# DA14531 register map
Vendor: Dialog; Series: DA14531; File version: 1.2
CPU: CM0 r1p0, little endian, MPU, FPU, 3 interrupt priority bits
Registers are 16-bit, read-write, reset 0x0 unless marked. A register's access mark holds for its fields unless they carry their own. Offsets are from the block's base; [hi:lo] are bit positions.

## SPI — SPI registers
Base 0x50001200
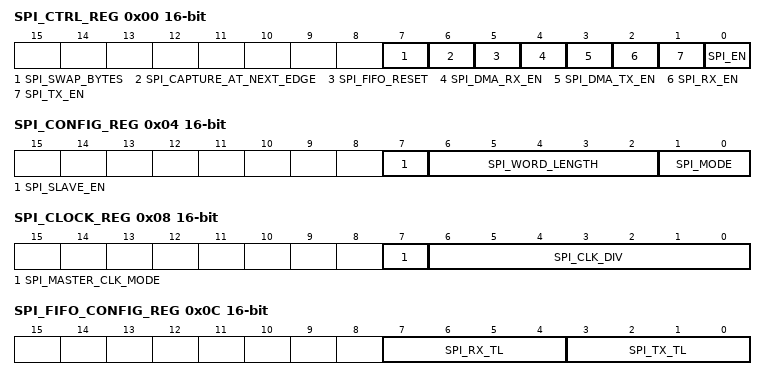
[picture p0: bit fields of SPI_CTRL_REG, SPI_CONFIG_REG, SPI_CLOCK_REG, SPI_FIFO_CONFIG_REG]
0x00 SPI_CTRL_REG — Spi control register
  [7] SPI_SWAP_BYTES — 0 = normal operation 1 = LSB and MSB are swaped in APB interface In case of 8bit spi interface, DMA/SPI can be configured in 16bit mode to off load the bus. Enabling SPI_SWAP_BYTES bytes will read/wrte correctly
  [6] SPI_CAPTURE_AT_NEXT_EDGE — 0 = SPI captures data at correct clock edge 1 = SPI captures data at next clock edge. (only for Master mode and high clock)
  [5] SPI_FIFO_RESET — 0 = Fifo normal operation 1 = Fifo in reset state
  [4] SPI_DMA_RX_EN — applicable only when SPI_RX_EN=1 0 = No DMA request for RX 1 = DMA request when SPI_STATUS_RX_FULL='1'
  [3] SPI_DMA_TX_EN — applicable only when SPI_TX_EN=1 0 = No DMA request for TX 1 = DMA request when SPI_STATUS_TX_EMPTY='1'
  [2] SPI_RX_EN — 0 = RX path is disabled 1 = RX path is enabled Note: if master clk async or spi mode=1 or spi mode=3 readonly is not supported
  [1] SPI_TX_EN — 0 = TX path is disabled 1 = TX path is enabled
  [0] SPI_EN — 0 = SPI module is disable 1 = SPI module is enable
0x04 SPI_CONFIG_REG — Spi control register
  [7] SPI_SLAVE_EN — 0 = SPI module master mode 1 = SPI module slave mode
  [6:2] SPI_WORD_LENGTH — Define the spi word length = 1+ SPI_WORD_LENGTH (range 4 to 32)
  [1:0] SPI_MODE — Define the spi mode (CPOL, CPHA) 0 = new data on falling, capture on rising, clk low in idle state 1 = new data on rising, capture on falling, Clk low in idle state 2 = new data on rising, capture on falling, Clk high in idle state 3 = new data on falling, capture on rising Clk high in idle state
0x08 SPI_CLOCK_REG — Spi clock register
  [7] SPI_MASTER_CLK_MODE — Should be always 1
  [6:0] SPI_CLK_DIV — Applicable only in master mode Defines the spi clock frequency in master only mode SPI_CLK = module_clk / 2*(SPI_CLK_DIV+1) when SPI_CLK_DIV not 0x7F if SPI_CLK_DIV=0x7F then SPI_CLK=module_clk
0x0C SPI_FIFO_CONFIG_REG — Spi fifo configuration register
  [7:4] SPI_RX_TL — Receive FIFO threshold level in bytes. Control the level of bytes in fifo that triggers the RX_FULL interrupt. IRQ is occurred when fifo level is more or equal to SPI_RX_TL+1. Fifo level is from 0 to 4
  [3:0] SPI_TX_TL — Transmit FIFO threshold level in bytes. Control the level of bytes in fifo that triggers the TX_EMPTY interrupt. IRQ is occurred when fifo level is less or equal to SPI_TX_TL. Fifo level is from 0 to 4
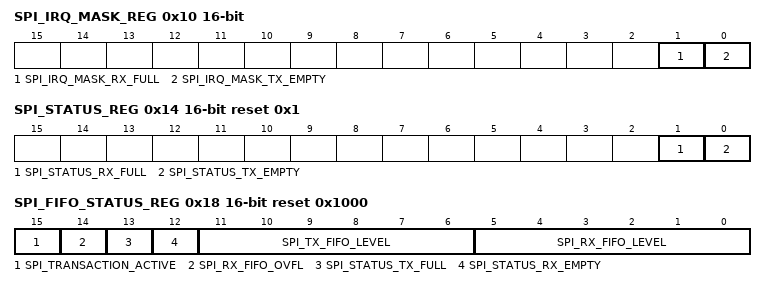
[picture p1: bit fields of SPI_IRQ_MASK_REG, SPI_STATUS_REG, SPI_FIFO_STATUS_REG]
0x10 SPI_IRQ_MASK_REG — Spi interrupt mask register
  [1] SPI_IRQ_MASK_RX_FULL — 0 = FIFO RX full irq is masked 1 = FIFO RX full irq is enabled
  [0] SPI_IRQ_MASK_TX_EMPTY — 0 = FIFO TX empty irq is masked 1 = FIFO TX empy irq is enabled
0x14 SPI_STATUS_REG reset 0x1 — Spi status register
  [1] SPI_STATUS_RX_FULL ro — Auto clear 0 = RX fifo level is less than SPI_RX_TL+1 1 = RX fifo level is more or equal to SPI_RX_TL+1
  [0] SPI_STATUS_TX_EMPTY ro — Auto clear 0 = TX fifo level is larger than SPI_TX_TL 1 = TX fifo level is less or equal to SPI_TX_TL
0x18 SPI_FIFO_STATUS_REG reset 0x1000 — SPI RX/TX fifo status register
  [15] SPI_TRANSACTION_ACTIVE ro — In master mode 0 = spi transaction is inactive 1 = spi transaction is active
  [14] SPI_RX_FIFO_OVFL ro — When 1, receive data is not written to fifo because fifo was full and interrupt is generated. It clears with SPI_CTRL_REG.SPI_FIFO_RESET
  [13] SPI_STATUS_TX_FULL ro — 0 = TX fifo is not full 1 = TX fifo is full
  [12] SPI_STATUS_RX_EMPTY ro — 0 = RX fifo is not empty 1 = RX fifo is empty
  [11:6] SPI_TX_FIFO_LEVEL ro — Gives the number of bytes in TX fifo
  [5:0] SPI_RX_FIFO_LEVEL ro — Gives the number of bytes in RX fifo
0x1C SPI_FIFO_READ_REG — Spi RX fifo read register
  [15:0] SPI_FIFO_READ ro — Read from RX fifo. Read access is permit only if SPI_STATUS_RX_EMPTY=0. Returns the 16 LSb
0x20 SPI_FIFO_WRITE_REG — Spi TX fifo wtite register
  [15:0] SPI_FIFO_WRITE wo — Write to TX fifo. Write access is permit only if SPI_STATUS_TX_FULL is 0
0x24 SPI_CS_CONFIG_REG — Spi cs configuration register
  [2:0] SPI_CS_SELECT — Control the cs output in master mode 0 = none slave device selected 1 = selected slave device connected to GPIO with FUNC_MODE=SPI_CS0 2 = selected slave device connected to GPIO with FUNC_MODE=SPI_CS1 4 = selected slave device connected to GPIO with FUNC_MODE=GPIO
0x28 SPI_FIFO_HIGH_REG — Spi TX/RX High 16bit word
  [15:0] SPI_FIFO_HIGH — RX/TX fifo data. 16 MSb when spi word is larger than 16bits This register has to be written before the SPI_FIFO_WRITE_REG This register has to be read after the SPI_FIFO_READ_REG
0x2C SPI_TXBUFFER_FORCE_L_REG — SPI TX buffer force low value
  [15:0] SPI_TXBUFFER_FORCE_L wo — Write directly the tx buffer (2 LSB). It must to be used only in slave mode
0x30 SPI_TXBUFFER_FORCE_H_REG — SPI TX buffer force high value
  [15:0] SPI_TXBUFFER_FORCE_H wo — Write directly the tx buffer (2 MSB). It must to be used only in slave mode. This register has to be written before the SPI_FIFO_WRITE_REG
